# RT58X register map
Series: ARMv8-M Mainline; File version: 1.0
CPU: CM3 r0p0, little endian, MPU, no FPU, VTOR, 3 interrupt priority bits
Registers are 32-bit, read-write, reset 0x0 unless marked. A register's access mark holds for its fields unless they carry their own. Offsets are from the block's base; [hi:lo] are bit positions.

## RT570_PMU — RT570_PMU Register block
Base 0x40200000
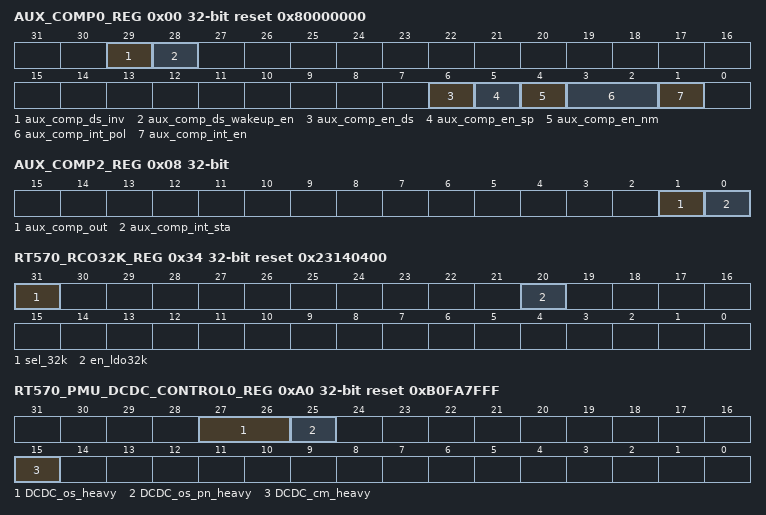
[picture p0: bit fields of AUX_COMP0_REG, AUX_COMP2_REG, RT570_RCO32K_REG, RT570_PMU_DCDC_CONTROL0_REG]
0x00 AUX_COMP0_REG reset 0x80000000 — aux comp0
  [29] aux_comp_ds_inv — Invert the aux_comp_out for waking up from DeepSleep. 0 : Not inverted. AUX COMP will wake up the system when aux_comp_out is low in DeepSleep. 1 : Inverted. AUX COMP will wake up the system when aux_comp_out is high in DeepSleep.
    0=B_29_ITEM0 (Not inverted. AUX COMP will wake up the system when aux_comp_out is low in DeepSleep.); 1=B_29_ITEM1 (Inverted. AUX COMP will wake up the system when aux_comp_out is high in DeepSleep.)
  [28] aux_comp_ds_wakeup_en — Enable AUX_COMP wakeup in DeepSleep when aux_comp_out is low (aux_comp_ds_inv==0) or high (aux_comp_ds_inv==1). Level trigger. 0 : disabled 1 : enabled
    0=B_28_ITEM0 (disabled); 1=B_28_ITEM1 (enabled)
  [6] aux_comp_en_ds — AUX comparator enable @deepsleep
    0=B_6 (AUX comparator enable @deepsleep)
  [5] aux_comp_en_sp — AUX comparator enable @sleep
    0=B_5 (AUX comparator enable @sleep)
  [4] aux_comp_en_nm — AUX comparator enable @normal 0: disable 1: enable
    0=B_4_ITEM0 (disable); 1=B_4_ITEM1 (enable)
  [3:2] aux_comp_int_pol — AUX comparator interrupt polarity 0: rising edge 1: falling edge 2: both edge
    0=B_2_to_3 (AUX comparator interrupt polarity 0: rising edge 1: falling edge 2: both edge)
  [1] aux_comp_int_en — AUX comparator interrupt enable 0: disable 1: enable
    0=B_1_ITEM0 (disable); 1=B_1_ITEM1 (enable)
0x04 AUX_COMP1_REG wo — aux comp1
  [0] aux_comp_int_clr — Write 1 to clear aux_comp_int_sta
    0=B_0 (Write 1 to clear aux_comp_int_sta)
0x08 AUX_COMP2_REG ro — aux comp2
  [1] aux_comp_out — aux_comp output
    0=B_1 (aux_comp output)
  [0] aux_comp_int_sta — aux_comp interrupt status 0: No interrupt 1: Interrupt pending
    0=B_0_ITEM0 (No interrupt); 1=B_0_ITEM1 (Interrupt pending)
0x10 RT570_TS_REG reset 0x20000000 — rt570 ts
  [31:30] test_aio_sel
    0=B_30_to_31 (test aio sel)
0x34 RT570_RCO32K_REG reset 0x23140400 — rt570 rco32k
  [31] sel_32k — No use.
    0=B_31 (No use.)
  [20] en_ldo32k — No use.
    0=B_20 (No use.)
0x9C RT570_PMU_BOD_SEL_REG reset 0xFF00000C — rt570 pmu bod sel
  [4] vdect — Shreshold voltages of supply dector
    0=B_4 (Shreshold voltages of supply dector)
0xA0 RT570_PMU_DCDC_CONTROL0_REG reset 0xB0FA7FFF — rt570 pmu dcdc control0
  [27:26] DCDC_os_heavy
    0=B_26_to_27 (dcdc os heavy)
  [25] DCDC_os_pn_heavy
    0=B_25 (dcdc os pn heavy)
  [15] DCDC_cm_heavy
    0=B_15 (dcdc cm heavy)
0xA4 RT570_PMU_DCDC_CONTROL1_REG reset 0xB0FA0888 — rt570 pmu dcdc control1
  [15] DCDC_cm_light
    0=B_15 (dcdc cm light)

## REMAP — REMAP Register block
Base 0x40500000
0x10 SW_IRQ_SET_REG — Write 1 to Set Software IRQ. Read for Software IRQ status.
0x14 SW_IRQ_CLR_REG — Write 1 Clear Software IRQ.
0x18 SW_IRQ_EN_SET_REG — Write 1 to Set Software IRQ Enable. Read for Software IRQ Enable status.
0x1C SW_IRQ_EN_CLR_REG — Write 1 to Clear Software IRQ Enable.

## UART0 — UART0 Register block
Base 0xA0000000
0x00 UART0_THR_RBR_REG — uart0 thr rbr
  [7:0] THR_RBR — For write, data to be transmitted. For read, received data.
    0=B_0_to_7 (For write, data to be transmitted. For read, received data.)
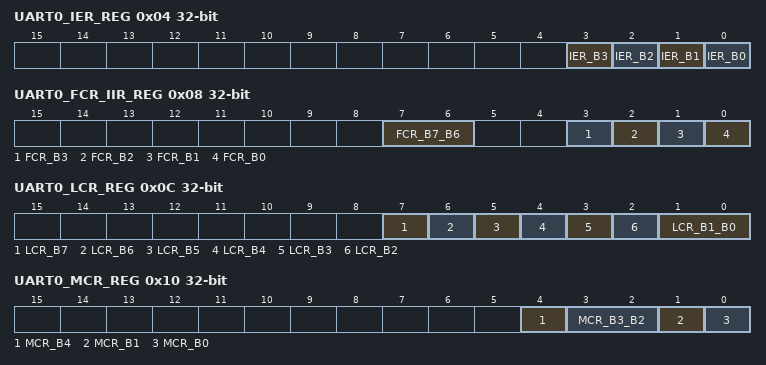
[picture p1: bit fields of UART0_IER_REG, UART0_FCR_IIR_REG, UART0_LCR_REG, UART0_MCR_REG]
0x04 UART0_IER_REG — uart0 ier
  [3] IER_B3 — Enable MODEM Status Interrupt.
    0=B_3 (Enable MODEM Status Interrupt.)
  [2] IER_B2 — Enable Receiver Line Status Interrupt.
    0=B_2 (Enable Receiver Line Status Interrupt.)
  [1] IER_B1 — Enable Transmitter Holding Register Interrupt.
    0=B_1 (Enable Transmitter Holding Register Interrupt.)
  [0] IER_B0 — Enable Received Data Available Interrupt.
    0=B_0 (Enable Received Data Available Interrupt.)
0x08 UART0_FCR_IIR_REG — uart0 fcr iir
  [7:6] FCR_B7_B6 — Receiver Trigger Level.
    0=B_6_to_7 (Receiver Trigger Level.)
  [3] FCR_B3 — DMA Mode Select. Only support 16550 Mode 1.
    0=B_3 (DMA Mode Select. Only support 16550 Mode 1.)
  [2] FCR_B2 — Transmit FIFO reset (self-clearing).
    0=B_2 (Transmit FIFO reset (self-clearing).)
  [1] FCR_B1 — Receive FIFO reset (self-clearing).
    0=B_1 (Receive FIFO reset (self-clearing).)
  [0] FCR_B0 — FIFO Enable.
    0=B_0 (FIFO Enable.)
0x0C UART0_LCR_REG — uart0 lcr
  [7] LCR_B7 — Divisor Latch Access (DLAB).
    0=B_7 (Divisor Latch Access (DLAB).)
  [6] LCR_B6 — Set Break.
    0=B_6 (Set Break.)
  [5] LCR_B5 — Stick Parity.
    0=B_5 (Stick Parity.)
  [4] LCR_B4 — Even Parity Select.
    0=B_4 (Even Parity Select.)
  [3] LCR_B3 — Parity Enable.
    0=B_3 (Parity Enable.)
  [2] LCR_B2 — Number of Stop Bits.
    0=B_2 (Number of Stop Bits.)
  [1:0] LCR_B1_B0 — Word Length Select. 0: 5-bit data 1: 6-bit data 2: 7-bit data 3: 8-bit data
    0=B_0_to_1 (Word Length Select. 0: 5-bit data 1: 6-bit data 2: 7-bit data 3: 8-bit data)
0x10 UART0_MCR_REG — uart0 mcr
  [4] MCR_B4 — Loopback mode select.
    0=B_4 (Loopback mode select.)
  [3:2] MCR_B3_B2 — Auxiliary user designated output.
    0=B_2_to_3 (Auxiliary user designated output.)
  [1] MCR_B1 — Request to Send (RTS).
    0=B_1 (Request to Send (RTS).)
  [0] MCR_B0 — Data Terminal Ready (DTR).
    0=B_0 (Data Terminal Ready (DTR).)
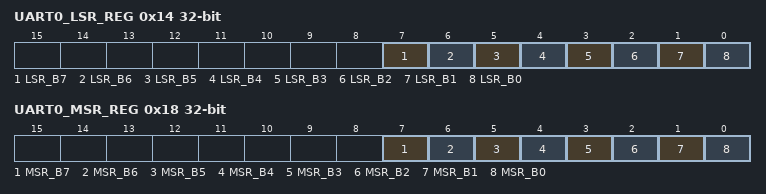
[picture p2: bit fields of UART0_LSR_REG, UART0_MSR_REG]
0x14 UART0_LSR_REG ro — uart0 lsr
  [7] LSR_B7 — Error in Receiver FIFO.
    0=B_7 (Error in Receiver FIFO.)
  [6] LSR_B6 — Transmitter Empty.
    0=B_6 (Transmitter Empty.)
  [5] LSR_B5 — Transmitter Holding Register Empty.
    0=B_5 (Transmitter Holding Register Empty.)
  [4] LSR_B4 — Break Interrupt.
    0=B_4 (Break Interrupt.)
  [3] LSR_B3 — Framing Error.
    0=B_3 (Framing Error.)
  [2] LSR_B2 — Parity Error.
    0=B_2 (Parity Error.)
  [1] LSR_B1 — Overrun Error.
    0=B_1 (Overrun Error.)
  [0] LSR_B0 — Data Ready (DR).
    0=B_0 (Data Ready (DR).)
0x18 UART0_MSR_REG ro — uart0 msr
  [7] MSR_B7 — Data Carrier Detect (DCD).
    0=B_7 (Data Carrier Detect (DCD).)
  [6] MSR_B6 — Ring Indicator (RI).
    0=B_6 (Ring Indicator (RI).)
  [5] MSR_B5 — Data Set Ready (DSR).
    0=B_5 (Data Set Ready (DSR).)
  [4] MSR_B4 — Clear To Send (CTS).
    0=B_4 (Clear To Send (CTS).)
  [3] MSR_B3 — Delta Data Carrier Detect (DDCD).
    0=B_3 (Delta Data Carrier Detect (DDCD).)
  [2] MSR_B2 — Trailing Edge Ring Indicator (TERI).
    0=B_2 (Trailing Edge Ring Indicator (TERI).)
  [1] MSR_B1 — Delta Data Set Ready (DDSR).
    0=B_1 (Delta Data Set Ready (DDSR).)
  [0] MSR_B0 — Delta Clear To Send (DCTS).
    0=B_0 (Delta Clear To Send (DCTS).)
0x1C UART0_SCR_REG — uart0 scr
  [7:0] SCR_B7_B0 — Scratchpad register.
    0=B_0_to_7 (Scratchpad register.)
